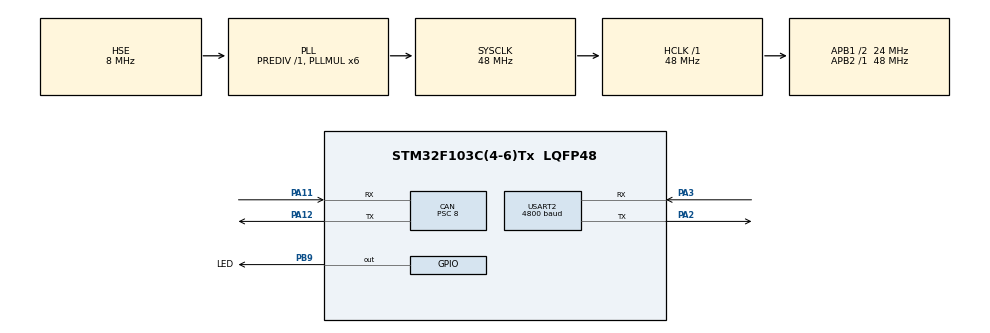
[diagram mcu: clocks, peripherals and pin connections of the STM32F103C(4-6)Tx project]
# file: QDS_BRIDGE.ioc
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CAN.ABOM=DISABLE
CAN.AWUM=ENABLE
CAN.BS1=CAN_BS1_3TQ
CAN.BS2=CAN_BS2_8TQ
CAN.CalculateBaudRate=250000
CAN.CalculateTimeBit=3999.99
CAN.CalculateTimeQuantum=333.3333333333333
CAN.Mode=CAN_MODE_NORMAL
CAN.Prescaler=8
Dma.Request0=USART2_RX
Dma.USART2_RX.0.Direction=DMA_PERIPH_TO_MEMORY
Dma.USART2_RX.0.Instance=DMA1_Channel6
Dma.USART2_RX.0.MemDataAlignment=DMA_MDATAALIGN_BYTE
Dma.USART2_RX.0.MemInc=DMA_MINC_ENABLE
Dma.USART2_RX.0.Mode=DMA_NORMAL
Dma.USART2_RX.0.PeriphDataAlignment=DMA_PDATAALIGN_BYTE
Dma.USART2_RX.0.PeriphInc=DMA_PINC_DISABLE
Dma.USART2_RX.0.Priority=DMA_PRIORITY_LOW
Mcu.Family=STM32F1
Mcu.Name=STM32F103C(4-6)Tx
Mcu.Package=LQFP48
NVIC.DMA1_Channel6_IRQn=true\:0\:0\:false\:false\:true\:false\:true
NVIC.PriorityGroup=NVIC_PRIORITYGROUP_4
NVIC.TIM2_IRQn=true\:0\:0\:false\:false\:true\:true\:true
NVIC.USART2_IRQn=true\:0\:0\:false\:false\:true\:true\:true
NVIC.USB_LP_CAN1_RX0_IRQn=true\:0\:0\:false\:false\:true\:true\:true
PA11.Mode=CAN_Activate
PA11.Signal=CAN_RX
PA12.Mode=CAN_Activate
PA12.Signal=CAN_TX
PA13.Mode=Serial_Wire
PA13.Signal=SYS_JTMS-SWDIO
PA14.Mode=Serial_Wire
PA14.Signal=SYS_JTCK-SWCLK
PA2.Mode=Asynchronous
PA2.Signal=USART2_TX
PA3.Mode=Asynchronous
PA3.Signal=USART2_RX
PB9.GPIO_Label=LED
PB9.Signal=GPIO_Output
PD0-OSC_IN.Mode=HSE-External-Oscillator
PD0-OSC_IN.Signal=RCC_OSC_IN
PD1-OSC_OUT.Mode=HSE-External-Oscillator
PD1-OSC_OUT.Signal=RCC_OSC_OUT
ProjectManager.HeapSize=0x200
ProjectManager.StackSize=0x400
ProjectManager.TargetToolchain=STM32CubeIDE
RCC.AHBFreq_Value=48000000
RCC.APB1CLKDivider=RCC_HCLK_DIV2
RCC.APB1Freq_Value=24000000
RCC.APB1TimFreq_Value=48000000
RCC.APB2Freq_Value=48000000
RCC.APB2TimFreq_Value=48000000
RCC.HCLKFreq_Value=48000000
RCC.PLLMUL=RCC_PLL_MUL6
RCC.PLLSourceVirtual=RCC_PLLSOURCE_HSE
RCC.SYSCLKFreq_VALUE=48000000
RCC.SYSCLKSource=RCC_SYSCLKSOURCE_PLLCLK
RCC.USBFreq_Value=48000000
USART2.BaudRate=4800
USART2.VirtualMode=VM_ASYNC
VP_IWDG_VS_IWDG.Mode=IWDG_Activate
VP_TIM2_VS_ClockSourceINT.Mode=Internal
board=custom

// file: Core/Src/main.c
/* USER CODE BEGIN Header */
/**
  ******************************************************************************
  * @file           : main.c
  * @brief          : Main program body
  ******************************************************************************
  * @attention
  *
  * <h2><center>&copy; Copyright (c) 2021 STMicroelectronics.
  * All rights reserved.</center></h2>
  *
  * This software component is licensed by ST under BSD 3-Clause license,
  * the "License"; You may not use this file except in compliance with the
  * License. You may obtain a copy of the License at:
  *                        opensource.org/licenses/BSD-3-Clause
  *
  ******************************************************************************
  */
/* USER CODE END Header */
#include "main.h"
#include "can.h"
#include "dma.h"
#include "iwdg.h"
#include "tim.h"
#include "usart.h"
#include "gpio.h"

/* USER CODE BEGIN Includes */
#include "includes.h"
/* USER CODE END Includes */

/* USER CODE BEGIN PTD */
uint8_t test[] = {0xaa,0xbb,0xcc,0xdd,0xee,0xff,0xaa,0xbb,0xcc,0xdd,0xee,0xff,0xaa,0xbb,0xcc,0xdd,0xee,0xff,0xaa,0xbb,0xcc,0xdd,0xee,0x11,0x33,0x55};

/* USER CODE END PTD */

/* USER CODE BEGIN PM */
uint8_t data[8]={1,2,3,4,5,6,7,8};
/* USER CODE END PM */

void SystemClock_Config(void);

int main(void)
{

  /* MCU Configuration--------------------------------------------------------*/

  /* Reset of all peripherals, Initializes the Flash interface and the Systick. */
  HAL_Init();

  /* Configure the system clock */
  SystemClock_Config();

  /* Initialize all configured peripherals */
  MX_GPIO_Init();
  MX_CAN_Init();
  MX_IWDG_Init();
  MX_TIM2_Init();
  MX_DMA_Init();
  MX_USART2_UART_Init();
  /* USER CODE BEGIN 2 */
  uart_module_init(&signal_wire_huart_module, &huart2, &hdma_usart2_rx);
  HAL_TIM_Base_Start(&htim2);
  CAN1_Config();   //调用过滤器函
  /* USER CODE END 2 */

  /* Infinite loop */
  while (1)
  {

    /* USER CODE BEGIN 3 */
	  HAL_IWDG_Refresh(&hiwdg); //iwdg

	  HAL_GPIO_TogglePin(LED_GPIO_Port, LED_Pin);
	  //signal_wire_read_handler();
	  HAL_Delay(250);
	 // CAN_senddata(&hcan);
	  bat_charge_management();

	 // signle_test();
	 // CAN_senddata(&hcan);
	 // CAN_Send_Pack(test,sizeof(test));
	//  Can_TxMessage(0,0x222,8,data);//想要发送的报文数据
	 // uart_module_send_hex(data,sizeof(data));
	 // HAL_UART_Transmit(&huart2, data, sizeof(data), 1000);

  }
  /* USER CODE END 3 */
}

void SystemClock_Config(void)
{
  RCC_OscInitTypeDef RCC_OscInitStruct = {0};
  RCC_ClkInitTypeDef RCC_ClkInitStruct = {0};

  /** Initializes the RCC Oscillators according to the specified parameters
  * in the RCC_OscInitTypeDef structure.
  */
  RCC_OscInitStruct.OscillatorType = RCC_OSCILLATORTYPE_LSI|RCC_OSCILLATORTYPE_HSE;
  RCC_OscInitStruct.HSEState = RCC_HSE_ON;
  RCC_OscInitStruct.HSEPredivValue = RCC_HSE_PREDIV_DIV1;
  RCC_OscInitStruct.HSIState = RCC_HSI_ON;
  RCC_OscInitStruct.LSIState = RCC_LSI_ON;
  RCC_OscInitStruct.PLL.PLLState = RCC_PLL_ON;
  RCC_OscInitStruct.PLL.PLLSource = RCC_PLLSOURCE_HSE;
  RCC_OscInitStruct.PLL.PLLMUL = RCC_PLL_MUL6;
  if (HAL_RCC_OscConfig(&RCC_OscInitStruct) != HAL_OK)
  {
    Error_Handler();
  }
  /** Initializes the CPU, AHB and APB buses clocks
  */
  RCC_ClkInitStruct.ClockType = RCC_CLOCKTYPE_HCLK|RCC_CLOCKTYPE_SYSCLK
                              |RCC_CLOCKTYPE_PCLK1|RCC_CLOCKTYPE_PCLK2;
  RCC_ClkInitStruct.SYSCLKSource = RCC_SYSCLKSOURCE_PLLCLK;
  RCC_ClkInitStruct.AHBCLKDivider = RCC_SYSCLK_DIV1;
  RCC_ClkInitStruct.APB1CLKDivider = RCC_HCLK_DIV2;
  RCC_ClkInitStruct.APB2CLKDivider = RCC_HCLK_DIV1;

  if (HAL_RCC_ClockConfig(&RCC_ClkInitStruct, FLASH_LATENCY_1) != HAL_OK)
  {
    Error_Handler();
  }
}

void Error_Handler(void)
{
  __disable_irq();
  while (1)
  {
  }
}

/************************ (C) COPYRIGHT STMicroelectronics *****END OF FILE****/
